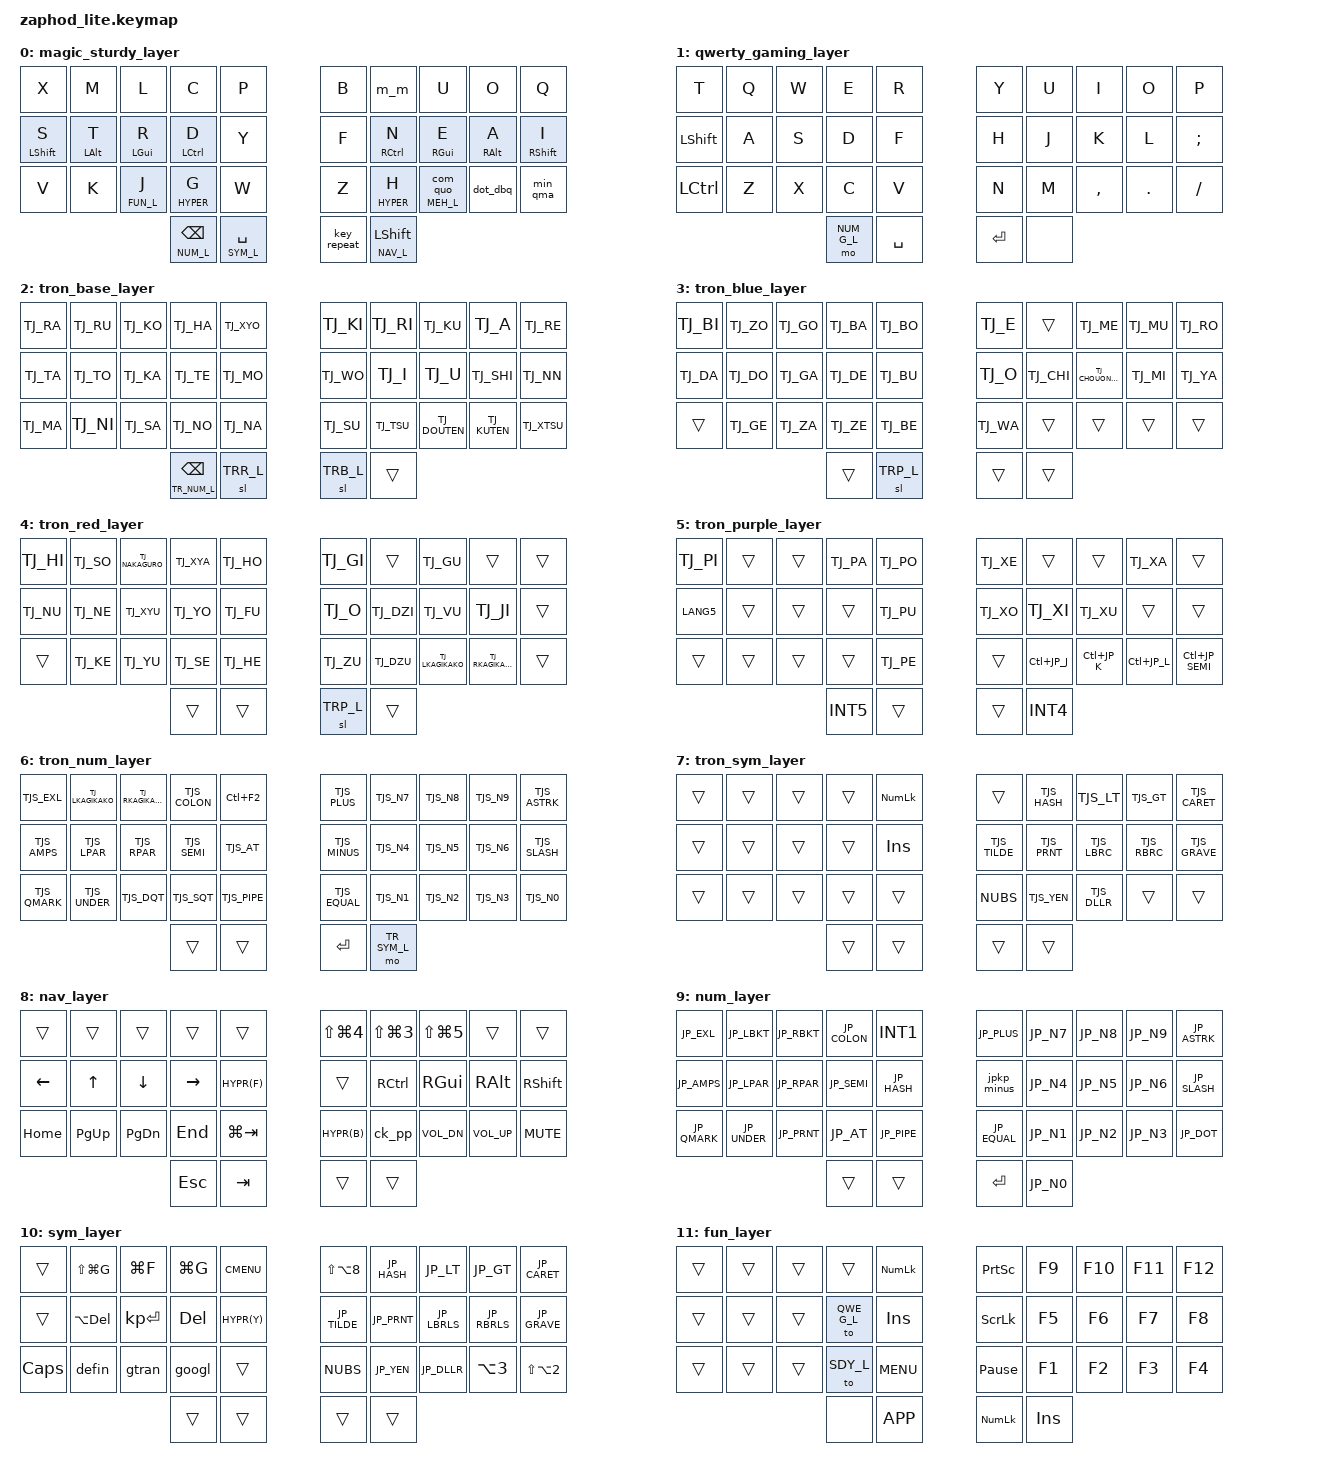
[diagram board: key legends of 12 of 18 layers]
// -*- mode: c++ -*-


/*
 * Copyright (c) 2021 Pete Johanson
 *
 * SPDX-License-Identifier: MIT
 */

#include <behaviors.dtsi>
#include <dt-bindings/zmk/keys.h>
#include <dt-bindings/zmk/bt.h>
#include <dt-bindings/zmk/outputs.h>

#define SDY_L 0
#define QWE_G_L 1

#define TRN_L 2
#define TRB_L 3
#define TRR_L 4
#define TRP_L 5

#define TR_NUM_L 6
#define TR_SYM_L 7

#define NAV_L 8
#define NUM_L 9
#define SYM_L 10
#define FUN_L 11

#define NUM_G_L 12

#define NUM_W_L 13
#define BLE_L 14
#define MEH_L 15
#define SRT_EXW_MAC_L 16
#define SRT_EXL_L 17

#define HYPER LS(LA(LG(LCTL)))
#define MEH(key) LS(LA(LC(key)))
#define HYPR(key) LS(LA(LG(LC(key))))


// JIS

#include "jis.h"
#include "tron.h"

// Using layer taps on thumbs, having quick tap as well helps w/ repeating space/backspace
&lt { quick_tap_ms = <150>; };

&sk {  // sticky-key config
  release-after-ms = <1000>;  // release after 0.6s
  quick-release;             // no double capitalization when rolling keys
};

&sl {  // sticky-layer config
  release-after-ms = <5000>;  
  quick-release;             // no double capitalization when rolling keys
};

&caps_word {
  continue-list = <UNDERSCORE INT1 MINUS AMPS BACKSPACE>;
};

/ {
  combos {
    compatible = "zmk,combos";
    // system
    ble_mo {
      timeout-ms = <50>;
      key-positions = <9 19 29>;
      bindings = <&mo BLE_L>;
      require-prior-idle-ms = <180>;
    };
    // layers
    num_sticky_combo {
      timeout-ms = <50>;
      key-positions = <12 30>;
      bindings = <&sl NUM_L>;
      require-prior-idle-ms = <180>;
    };
    nav_sticky_combo {
      timeout-ms = <50>;
      key-positions = <11 30>;
      bindings = <&sl NAV_L>;
      require-prior-idle-ms = <180>;
    };
    sym_sticky_combo {
      timeout-ms = <50>;
      key-positions = <10 30>;
      bindings = <&sl SYM_L>;
      require-prior-idle-ms = <180>;
    };
    num_word_combo {
      timeout-ms = <50>;
      key-positions = <30 33>;
      bindings = <&tog NUM_W_L>;
      require-prior-idle-ms = <180>;
    };
    fun_alt_combo {
      timeout-ms = <50>;
      key-positions = <8 18 28>;
      bindings = <&mo FUN_L>;
      require-prior-idle-ms = <180>;
    };
    // English
    caps_word_combo {
      timeout-ms = <50>;
      key-positions = <31 32>;
      bindings = <&caps_word>;
      require-prior-idle-ms = <180>;
    };
    sorcery_magic2 {
      timeout-ms = <50>;
      key-positions = <3 6>;
      layers = <0 2>;
      bindings = <&kp LS(NUBS)>;
      require-prior-idle-ms = <180>;
    };
    // Numword
    panic {
      timeout-ms = <50>;
      key-positions = <0 10>;
      layers = <13>;
      bindings = <&to SDY_L>;
      require-prior-idle-ms = <180>;
    };
    numword_ret {
      timeout-ms = <50>;
      key-positions = <18 8>;
      layers = <13>;
      require-prior-idle-ms = <180>;
      bindings = <&nw_ret>;
    }; 
    // movement
    backward_char {
      timeout-ms = <50>;
      key-positions = <12 22>;
      bindings = <&kp LEFT>;
      require-prior-idle-ms = <180>;
    };
    forward_char {
      timeout-ms = <50>;
      key-positions = <17 27>;
      bindings = <&kp RIGHT>;
      require-prior-idle-ms = <180>;
    };
    backward_sentence {
      timeout-ms = <50>;
      key-positions = <14 24>;
      bindings = <&kp HOME>;
      require-prior-idle-ms = <180>;
    };      
    forward_sentence {
      timeout-ms = <50>;
      key-positions = <15 25>;
      bindings = <&kp END>;
      require-prior-idle-ms = <180>;
    };
    previous_line {
      timeout-ms = <50>;
      key-positions = <13 22>;
      bindings = <&kp UP>;
      require-prior-idle-ms = <180>;
    };
    next_line {
      timeout-ms = <50>;
      key-positions = <16 27>;
      bindings = <&kp DOWN>;
      require-prior-idle-ms = <180>;
    };
    up {
      timeout-ms = <50>;
      key-positions = <13 23>;
      bindings = <&kp UP>;
      require-prior-idle-ms = <180>;
    };
    down {
      timeout-ms = <50>;
      key-positions = <16 26>;
      bindings = <&kp DOWN>;
      require-prior-idle-ms = <180>;
    };
    page_up_combo {
      timeout-ms = <50>;
      key-positions = <11 22>;
      bindings = <&kp PG_UP>;
      require-prior-idle-ms = <180>;
    };
    page_down_combo {
      timeout-ms = <50>;
      key-positions = <18 27>;
      bindings = <&kp PG_DN>;
      require-prior-idle-ms = <180>;
    };  
    // controls    
    tab_combo {
      timeout-ms = <50>;
      key-positions = <10 20>;
      bindings = <&kp TAB>;
      require-prior-idle-ms = <180>;
    };
    esc_combo {
      timeout-ms = <50>;
      key-positions = <0 10>;
      bindings = <&kp ESC>;
      require-prior-idle-ms = <180>;
    };
    bksp_word_combo_mac {
      timeout-ms = <50>;
      key-positions = <15 16>;
      layers = <0 2>;
      bindings = <&kp LA(BSPC)>;
      require-prior-idle-ms = <180>;
    };
    del_word_mac {
      timeout-ms = <50>;
      key-positions = <13 14>;
      layers = <0 2>;
      bindings = <&kp LA(DEL)>;
      require-prior-idle-ms = <180>;
    };
    spc_combo {
      layers = <2 3 4 5 6 7>;
      timeout-ms = <30>;
      key-positions = <11 21>;
      bindings = <&kp SPACE>;
      require-prior-idle-ms = <180>;
    };
    ret_combo {
      timeout-ms = <50>;
      key-positions = <18 8>;
      bindings = <&kp RET>;
      require-prior-idle-ms = <180>;
    };
    // shortcuts
    undo_mac {
      timeout-ms = <50>;
      key-positions = <3 4>;
      bindings = <&undo_mac_b>;
      require-prior-idle-ms = <180>;
    };
    save_mac {
      timeout-ms = <50>;
      key-positions = <28 18>;
      layers = <0 2>;
      bindings = <&kp LG(S)>;
      require-prior-idle-ms = <180>;
    };
    copy_mac {
      timeout-ms = <50>;
      key-positions = <1 11>;
      layers = <0 2>;
      bindings = <&copy_mac_b>;
      require-prior-idle-ms = <180>;
    };
    paste_mac {
      timeout-ms = <50>;
      key-positions = <2 12>;
      layers = <0 2>;
      bindings = <&paste_mac_b>;
      require-prior-idle-ms = <180>;
    };
    // Japanese language
    eisu_combo {
      timeout-ms = <50>;
      key-positions = <3 13>;
      layers = <0 2>;
      bindings = <&_EISU>;
      require-prior-idle-ms = <180>;
    };
    kana_combo {
      timeout-ms = <50>;
      key-positions = <6 16>;
      layers = <0 2>;
      bindings = <&_KANA>;
      require-prior-idle-ms = <180>;
    };
    hiragana_mac {
      layers = <1 2 3 4 5 6>;
      timeout-ms = <50>;
      key-positions = <4 14>;
      bindings = <&kp LC(J)>;
      require-prior-idle-ms = <180>;
    };
    katakana_mac {
      layers = <1 2 3 4 5 6>;
      timeout-ms = <50>;
      key-positions = <5 15>;
      bindings = <&kp LC(K)>;
      require-prior-idle-ms = <180>;
    };
    // select word-line
    selword_mac {
      timeout-ms = <50>;
      key-positions = <13 16>;
      layers = <0 2>;
      bindings = <&selw_sell_mac>;
      require-prior-idle-ms = <180>;
    };
    selword_rep_mac {
      layers = <14>;
      timeout-ms = <50>;
      key-positions = <13 16>;
      bindings = <&selword_f_mac_rep>;
      require-prior-idle-ms = <180>;
    };
    selline_rep {
      layers = <15>;
      timeout-ms = <50>;
      key-positions = <13 16>;
      bindings = <&selline_f_rep>;
      require-prior-idle-ms = <180>;
    };
    squot {
      timeout-ms = <50>;
      key-positions = <7 17>;
      bindings = <&kp LS(N7)>;
      require-prior-idle-ms = <180>;
    };
    dquot {
      timeout-ms = <50>;
      key-positions = <9 19>;
      bindings = <&kp LS(N2)>;
      require-prior-idle-ms = <180>;
    };
  };
};

/ {
  macros {
  TJ_GI: tron_gi {
      compatible = "zmk,behavior-macro";
      #binding-cells = <0>;
      bindings
        = <&macro_tap &kp TJ_KI>
        , <&macro_tap &kp TJ_DAKUTEN>
        ;
    };
  TJ_GE: tron_ge {
      compatible = "zmk,behavior-macro";
      #binding-cells = <0>;
      bindings
        = <&macro_tap &kp TJ_KE>
        , <&macro_tap &kp TJ_DAKUTEN>
        ;
    };
  TJ_GU: tron_gu {
      compatible = "zmk,behavior-macro";
      #binding-cells = <0>;
      bindings
        = <&macro_tap &kp TJ_KU>
        , <&macro_tap &kp TJ_DAKUTEN>
        ;
    };
  TJ_DZI: tron_dzi {
      compatible = "zmk,behavior-macro";
      #binding-cells = <0>;
      bindings
        = <&macro_tap &kp TJ_CHI>
        , <&macro_tap &kp TJ_DAKUTEN>
        ;
    };
  TJ_VU: tron_vu {
      compatible = "zmk,behavior-macro";
      #binding-cells = <0>;
      bindings
        = <&macro_tap &kp TJ_U>
        , <&macro_tap &kp TJ_DAKUTEN>
        ;
    };
  TJ_JI: tron_ji {
      compatible = "zmk,behavior-macro";
      #binding-cells = <0>;
      bindings
        = <&macro_tap &kp TJ_SHI>
        , <&macro_tap &kp TJ_DAKUTEN>
        ;
    };
  TJ_ZU: tron_zu {
      compatible = "zmk,behavior-macro";
      #binding-cells = <0>;
      bindings
        = <&macro_tap &kp TJ_SU>
        , <&macro_tap &kp TJ_DAKUTEN>
        ;
    };
  TJ_DZU: tron_dzu {
      compatible = "zmk,behavior-macro";
      #binding-cells = <0>;
      bindings
        = <&macro_tap &kp TJ_TSU>
        , <&macro_tap &kp TJ_DAKUTEN>
        ;
    };
  TJ_BI: tron_bi {
      compatible = "zmk,behavior-macro";
      #binding-cells = <0>;
      bindings
        = <&macro_tap &kp TJ_HI>
        , <&macro_tap &kp TJ_DAKUTEN>
        ;
    };
  TJ_ZO: tron_zo {
      compatible = "zmk,behavior-macro";
      #binding-cells = <0>;
      bindings
        = <&macro_tap &kp TJ_SO>
        , <&macro_tap &kp TJ_DAKUTEN>
        ;
    };
  TJ_GO: tron_go {
      compatible = "zmk,behavior-macro";
      #binding-cells = <0>;
      bindings
        = <&macro_tap &kp TJ_KO>
        , <&macro_tap &kp TJ_DAKUTEN>
        ;
    };
  TJ_BA: tron_ba {
      compatible = "zmk,behavior-macro";
      #binding-cells = <0>;
      bindings
        = <&macro_tap &kp TJ_HA>
        , <&macro_tap &kp TJ_DAKUTEN>
        ;
    };
  TJ_BO: tron_bo {
      compatible = "zmk,behavior-macro";
      #binding-cells = <0>;
      bindings
        = <&macro_tap &kp TJ_HO>
        , <&macro_tap &kp TJ_DAKUTEN>
        ;
    };
  TJ_DA: tron_da {
      compatible = "zmk,behavior-macro";
      #binding-cells = <0>;
      bindings
        = <&macro_tap &kp TJ_TA>
        , <&macro_tap &kp TJ_DAKUTEN>
        ;
    };
  TJ_DO: tron_do {
      compatible = "zmk,behavior-macro";
      #binding-cells = <0>;
      bindings
        = <&macro_tap &kp TJ_TO>
        , <&macro_tap &kp TJ_DAKUTEN>
        ;
    };
  TJ_GA: tron_ga {
      compatible = "zmk,behavior-macro";
      #binding-cells = <0>;
      bindings
        = <&macro_tap &kp TJ_KA>
        , <&macro_tap &kp TJ_DAKUTEN>
        ;
    };
  TJ_DE: tron_de {
      compatible = "zmk,behavior-macro";
      #binding-cells = <0>;
      bindings
        = <&macro_tap &kp TJ_TE>
        , <&macro_tap &kp TJ_DAKUTEN>
        ;
    };
  TJ_BU: tron_bu {
      compatible = "zmk,behavior-macro";
      #binding-cells = <0>;
      bindings
        = <&macro_tap &kp TJ_FU>
        , <&macro_tap &kp TJ_DAKUTEN>
        ;
    };
  TJ_ZE: tron_ze {
      compatible = "zmk,behavior-macro";
      #binding-cells = <0>;
      bindings
        = <&macro_tap &kp TJ_SE>
        , <&macro_tap &kp TJ_DAKUTEN>
        ;
    };
  TJ_ZA: tron_za {
      compatible = "zmk,behavior-macro";
      #binding-cells = <0>;
      bindings
        = <&macro_tap &kp TJ_SA>
        , <&macro_tap &kp TJ_DAKUTEN>
        ;
    };
  TJ_BE: tron_be {
      compatible = "zmk,behavior-macro";
      #binding-cells = <0>;
      bindings
        = <&macro_tap &kp TJ_HE>
        , <&macro_tap &kp TJ_DAKUTEN>
        ;
    };
  TJ_PA: tron_pa {
      compatible = "zmk,behavior-macro";
      #binding-cells = <0>;
      bindings
        = <&macro_tap &kp TJ_HA>
        , <&macro_tap &kp TJ_HANDAKUTEN>
        ;
    };
  TJ_PI: tron_pi {
      compatible = "zmk,behavior-macro";
      #binding-cells = <0>;
      bindings
        = <&macro_tap &kp TJ_HI>
        , <&macro_tap &kp TJ_HANDAKUTEN>
        ;
    };
  TJ_PU: tron_pu {
      compatible = "zmk,behavior-macro";
      #binding-cells = <0>;
      bindings
        = <&macro_tap &kp TJ_FU>
        , <&macro_tap &kp TJ_HANDAKUTEN>
        ;
    };
  TJ_PE: tron_pe {
      compatible = "zmk,behavior-macro";
      #binding-cells = <0>;
      bindings
        = <&macro_tap &kp TJ_HE>
        , <&macro_tap &kp TJ_HANDAKUTEN>
        ;
    };
  TJ_PO: tron_po {
      compatible = "zmk,behavior-macro";
      #binding-cells = <0>;
      bindings
        = <&macro_tap &kp TJ_HO>
        , <&macro_tap &kp TJ_HANDAKUTEN>
        ;
    };
  TJ_LKAGIKAKO: tron_lkagikako {
      compatible = "zmk,behavior-macro";
      #binding-cells = <0>;
      bindings
        = <&macro_press &kp LSHFT>
        , <&macro_tap &kp TJ_HANDAKUTEN>
        , <&macro_release &kp LSHFT>
        ;
    };
  TJ_RKAGIKAKO: tron_rkagikako {
      compatible = "zmk,behavior-macro";
      #binding-cells = <0>;
      bindings
        = <&macro_press &kp LSHFT>
        , <&macro_tap &kp TJ_MU>
        , <&macro_release &kp LSHFT>
        ;
    };
  TJS_QMARK: tron_question_mark {
      compatible = "zmk,behavior-macro";
      #binding-cells = <0>;
      bindings
        = <&macro_tap &kp TJ_NAKAGURO>
        , <&macro_tap &kp LC(L)>
        ;      
    };
  TJS_SLASH: tron_slash {
      compatible = "zmk,behavior-macro";
      #binding-cells = <0>;
      bindings
        = <&macro_tap &kp TJ_ME>
        , <&macro_tap &kp LC(L)>
        ;      
    };
  TJS_SEMI: tron_semi_colon {
      compatible = "zmk,behavior-macro";
      #binding-cells = <0>;
      bindings
        = <&macro_tap &kp TJ_RE>
        , <&macro_tap &kp LC(L)>
        ;      
    };
  TJS_COLON: tron_colon {
      compatible = "zmk,behavior-macro";
      #binding-cells = <0>;
      bindings
        = <&macro_tap &kp TJ_KE>
        , <&macro_tap &kp LC(L)>
        ;      
    };
  TJS_N1: tron_1 {
      compatible = "zmk,behavior-macro";
      #binding-cells = <0>;
      bindings
        = <&macro_tap &kp TJ_NU>
        , <&macro_tap &kp LC(L)>
        ;      
    };
  TJS_N2: tron_2 {
      compatible = "zmk,behavior-macro";
      #binding-cells = <0>;
      bindings
        = <&macro_tap &kp TJ_FU>
        , <&macro_tap &kp LC(L)>
        ;      
    };
  TJS_N3: tron_3 {
      compatible = "zmk,behavior-macro";
      #binding-cells = <0>;
      bindings
        = <&macro_tap &kp TJ_A>
        , <&macro_tap &kp LC(L)>
        ;      
    };
  TJS_N4: tron_4 {
      compatible = "zmk,behavior-macro";
      #binding-cells = <0>;
      bindings
        = <&macro_tap &kp TJ_U>
        , <&macro_tap &kp LC(L)>
        ;      
    };
  TJS_N5: tron_5 {
      compatible = "zmk,behavior-macro";
      #binding-cells = <0>;
      bindings
        = <&macro_tap &kp TJ_E>
        , <&macro_tap &kp LC(L)>
        ;      
    };
  TJS_N6: tron_6 {
      compatible = "zmk,behavior-macro";
      #binding-cells = <0>;
      bindings
        = <&macro_tap &kp TJ_O>
        , <&macro_tap &kp LC(L)>
        ;      
    };
  TJS_N7: tron_7 {
      compatible = "zmk,behavior-macro";
      #binding-cells = <0>;
      bindings
        = <&macro_tap &kp TJ_YA>
        , <&macro_tap &kp LC(L)>
        ;      
    };
  TJS_N8: tron_8 {
      compatible = "zmk,behavior-macro";
      #binding-cells = <0>;
      bindings
        = <&macro_tap &kp TJ_YU>
        , <&macro_tap &kp LC(L)>
        ;      
    };
  TJS_N9: tron_9 {
      compatible = "zmk,behavior-macro";
      #binding-cells = <0>;
      bindings
        = <&macro_tap &kp TJ_YO>
        , <&macro_tap &kp LC(L)>
        ;      
    };
  TJS_N0: tron_0 {
      compatible = "zmk,behavior-macro";
      #binding-cells = <0>;
      bindings
        = <&macro_tap &kp TJ_WA>
        , <&macro_tap &kp LC(L)>
        ;      
    };
  TJS_AT: tron_at {
      compatible = "zmk,behavior-macro";
      #binding-cells = <0>;
      bindings
        = <&macro_tap &kp TJ_DAKUTEN>
        , <&macro_tap &kp LC(L)>
        ;      
    };
  TJS_MINUS: tron_minus {
      compatible = "zmk,behavior-macro";
      #binding-cells = <0>;
      bindings
        = <&macro_tap &kp TJ_HO>
        , <&macro_tap &kp LC(L)>
        ;      
    };
  TJS_CARET: tron_circumflex {
      compatible = "zmk,behavior-macro";
      #binding-cells = <0>;
      bindings
        = <&macro_tap &kp TJ_HE>
        , <&macro_tap &kp LC(L)>
        ;      
    };
  TJS_UNDER: tron_underscore {
      compatible = "zmk,behavior-macro";
      #binding-cells = <0>;
      bindings
        = <&macro_tap &kp TJ_RO>
        , <&macro_tap &kp LC(L)>
        ;      
    };
  TJS_YEN: tron_yen {
      compatible = "zmk,behavior-macro";
      #binding-cells = <0>;
      bindings
        = <&macro_tap &kp TJ_CHOUONNPU>
        , <&macro_tap &kp LC(L)>
        ;      
    };
  TJS_EXL: tron_exclamation_mark {
      compatible = "zmk,behavior-macro";
      #binding-cells = <0>;
      bindings
        = <&macro_press &kp LSHFT>
        , <&macro_tap &kp TJ_NU>
        , <&macro_release &kp LSHFT>
        , <&macro_tap &kp LC(L)>
        ;      
    };
  TJS_DQT: tron_double_quote {
      compatible = "zmk,behavior-macro";
      #binding-cells = <0>;
      bindings
        = <&macro_press &kp LSHFT>
        , <&macro_tap &kp TJ_FU>
        , <&macro_release &kp LSHFT>
        , <&macro_tap &kp LC(L)>
        ;      
    };
  TJS_HASH: tron_hash {
      compatible = "zmk,behavior-macro";
      #binding-cells = <0>;
      bindings
        = <&macro_press &kp LSHFT>
        , <&macro_tap &kp TJ_A>
        , <&macro_release &kp LSHFT>
        , <&macro_tap &kp LC(L)>
        ;      
    };
  TJS_DLLR: tron_dollar {
      compatible = "zmk,behavior-macro";
      #binding-cells = <0>;
      bindings
        = <&macro_press &kp LSHFT>
        , <&macro_tap &kp TJ_U>
        , <&macro_release &kp LSHFT>
        , <&macro_tap &kp LC(L)>
        ;      
    };
  TJS_PRNT: tron_percent {
      compatible = "zmk,behavior-macro";
      #binding-cells = <0>;
      bindings
        = <&macro_press &kp LSHFT>
        , <&macro_tap &kp TJ_E>
        , <&macro_release &kp LSHFT>
        , <&macro_tap &kp LC(L)>
        ;      
    };
  TJS_AMPS: tron_ampersand {
      compatible = "zmk,behavior-macro";
      #binding-cells = <0>;
      bindings
        = <&macro_press &kp LSHFT>
        , <&macro_tap &kp TJ_O>
        , <&macro_release &kp LSHFT>
        , <&macro_tap &kp LC(L)>
        ;      
    };
  TJS_SQT: tron_single_quote {
      compatible = "zmk,behavior-macro";
      #binding-cells = <0>;
      bindings
        = <&macro_press &kp LSHFT>
        , <&macro_tap &kp TJ_YA>
        , <&macro_release &kp LSHFT>
        , <&macro_tap &kp LC(L)>
        ;      
    };
  TJS_LPAR: tron_left_parenthesis {
      compatible = "zmk,behavior-macro";
      #binding-cells = <0>;
      bindings
        = <&macro_press &kp LSHFT>
        , <&macro_tap &kp TJ_YU>
        , <&macro_release &kp LSHFT>
        , <&macro_tap &kp LC(L)>
        ;      
    };
  TJS_RPAR: tron_right_parenthesis {
      compatible = "zmk,behavior-macro";
      #binding-cells = <0>;
      bindings
        = <&macro_press &kp LSHFT>
        , <&macro_tap &kp TJ_YO>
        , <&macro_release &kp LSHFT>
        , <&macro_tap &kp LC(L)>
        ;      
    };
  TJS_EQUAL: tron_equal {
      compatible = "zmk,behavior-macro";
      #binding-cells = <0>;
      bindings
        = <&macro_press &kp LSHFT>
        , <&macro_tap &kp TJ_HO>
        , <&macro_release &kp LSHFT>
        , <&macro_tap &kp LC(L)>
        ;      
    };
  TJS_TILDE: tron_tilde {
      compatible = "zmk,behavior-macro";
      #binding-cells = <0>;
      bindings
        = <&macro_press &kp LSHFT>
        , <&macro_tap &kp TJ_HE>
        , <&macro_release &kp LSHFT>
        , <&macro_tap &kp LC(L)>
        ;      
    };
  TJS_PIPE: tron_pipe {
      compatible = "zmk,behavior-macro";
      #binding-cells = <0>;
      bindings
        = <&macro_press &kp LSHFT>
        , <&macro_tap &kp TJ_CHOUONNPU>
        , <&macro_release &kp LSHFT>
        , <&macro_tap &kp LC(L)>
        ;      
    };
  TJS_GRAVE: tron_grave {
      compatible = "zmk,behavior-macro";
      #binding-cells = <0>;
      bindings
        = <&macro_press &kp LSHFT>
        , <&macro_tap &kp TJ_DAKUTEN>
        , <&macro_release &kp LSHFT>
        , <&macro_tap &kp LC(L)>
        ;      
    };
  TJS_LBRC: tron_left_brace {
      compatible = "zmk,behavior-macro";
      #binding-cells = <0>;
      bindings
        = <&macro_press &kp LSHFT>
        , <&macro_tap &kp TJ_HANDAKUTEN>
        , <&macro_release &kp LSHFT>
        , <&macro_tap &kp LC(L)>
        ;      
    };
  TJS_RBRC: tron_right_brace {
      compatible = "zmk,behavior-macro";
      #binding-cells = <0>;
      bindings
        = <&macro_press &kp LSHFT>
        , <&macro_tap &kp TJ_MU>
        , <&macro_release &kp LSHFT>
        , <&macro_tap &kp LC(L)>
        ;      
    };
  TJS_PLUS: tron_plus {
      compatible = "zmk,behavior-macro";
      #binding-cells = <0>;
      bindings
        = <&macro_press &kp LSHFT>
        , <&macro_tap &kp TJ_RE>
        , <&macro_release &kp LSHFT>
        , <&macro_tap &kp LC(L)>
        ;      
    };
  TJS_ASTRK: tron_asterisk {
      compatible = "zmk,behavior-macro";
      #binding-cells = <0>;
      bindings
        = <&macro_press &kp LSHFT>
        , <&macro_tap &kp TJ_KE>
        , <&macro_release &kp LSHFT>
        , <&macro_tap &kp LC(L)>
        ;      
    };
  TJS_LT: tron_less_than {
      compatible = "zmk,behavior-macro";
      #binding-cells = <0>;
      bindings
        = <&macro_press &kp LSHFT>
        , <&macro_tap &kp TJ_DOUTEN>
        , <&macro_release &kp LSHFT>
        , <&macro_tap &kp LC(L)>
        ;      
    };
  TJS_GT: tron_greater_than {
      compatible = "zmk,behavior-macro";
      #binding-cells = <0>;
      bindings
        = <&macro_press &kp LSHFT>
        , <&macro_tap &kp TJ_KUTEN>
        , <&macro_release &kp LSHFT>
        , <&macro_tap &kp LC(L)>
        ;      
    };
  _EISU: _eisu {
      compatible = "zmk,behavior-macro";
      #binding-cells = <0>;
      bindings
        = <&macro_tap &kp LANG2>
        , <&macro_tap &to SDY_L>
        ;
    };
  _KANA: _kana {
      compatible = "zmk,behavior-macro";
      #binding-cells = <0>;
      bindings
        = <&macro_tap &kp LANG1>
        , <&macro_tap &to TRN_L>
        ;
    };
  googl: googl {
      compatible = "zmk,behavior-macro";
      #binding-cells = <0>;
      bindings
        = <&macro_tap &kp LG(C)>
        , <&macro_tap &kp LG(SPACE)>
        , <&macro_tap &kp G &kp SPACE>
        , <&macro_tap &kp LG(V) &kp RET>
        ;
    };
  gtran: gtran {
      compatible = "zmk,behavior-macro";
      #binding-cells = <0>;
      bindings
        = <&macro_tap &kp LG(C)>
        , <&macro_tap &kp LG(SPACE)>
        , <&macro_tap &kp T &kp SPACE>
        , <&macro_tap &kp LG(V) &kp RET>
        ;
    };
  defin: defin {
      compatible = "zmk,behavior-macro";
      #binding-cells = <0>;
      bindings
        = <&macro_tap &kp LG(C)>
        , <&macro_tap &kp LG(SPACE)>
        , <&macro_tap &kp D &kp SPACE>
        , <&macro_tap &kp LG(V)>
        , <&macro_wait_time 50>
        , <&kp RET>
        ;
    };

  nw_spc: nw_spc {
      compatible = "zmk,behavior-macro";
      #binding-cells = <0>;
      bindings
        = <&macro_press &kp SPACE>
        , <&macro_tap &tog NUM_W_L>
        , <&macro_pause_for_release>
        , <&macro_release &kp SPACE>
        ;
    };
  nw_ret: nw_ret {
      compatible = "zmk,behavior-macro";
      #binding-cells = <0>;
      bindings
        = <&macro_press &kp RET>
        , <&macro_tap &tog NUM_W_L>
        , <&macro_pause_for_release>
        , <&macro_release &kp RET>
        ;
    };
  selword_f_mac: select_word_mac_forwards {
      compatible = "zmk,behavior-macro";
      #binding-cells = <0>;
      bindings
        = <&macro_tap &kp LA(RIGHT)>
        , <&macro_tap &kp LA(LEFT)>
        , <&macro_tap &kp LA(LS(RIGHT))>
        , <&macro_tap &sl SRT_EXW_MAC_L>
        ;
    };
  selword_f_mac_rep: select_word_mac_forwards_repeat {
      compatible = "zmk,behavior-macro";
      #binding-cells = <0>;
      bindings
        = <&macro_tap &kp LA(LS(RIGHT))>
        , <&macro_tap &sl SRT_EXW_MAC_L>
        ;
    };
  selline_f: select_line_forwards {
      compatible = "zmk,behavior-macro";
      #binding-cells = <0>;
      bindings
        = <&macro_tap &kp HOME &kp LS(END)>
        , <&macro_tap &sl SRT_EXL_L>
        ;
    };
  selline_f_rep: select_line_forwards_repeat {
      compatible = "zmk,behavior-macro";
      #binding-cells = <0>;
      bindings    
        = <&macro_tap &kp LS(DOWN)>
        , <&macro_tap &kp LS(END)>
        , <&macro_tap &sl SRT_EXL_L>
        ;
    };
  undo_mac_b: undo_mac_b {
      compatible = "zmk,behavior-macro";
      #binding-cells = <0>;
      bindings =  <&kp (LG(Z))>;
    };
  copy_mac_b: copy_mac_b {
      compatible = "zmk,behavior-macro";
      #binding-cells = <0>;
      bindings =  <&kp (LG(C))>;
    };
  paste_mac_b: paste_mac_b {
      compatible = "zmk,behavior-macro";
      #binding-cells = <0>;
      bindings =  <&kp (LG(V))>;
    };
  };
  
  };
/ {
  behaviors {
  hm: homerow_mods {
      compatible = "zmk,behavior-hold-tap";
      #binding-cells = <2>;
      tapping_term_ms = <300>;
      require-prior-idle-ms = <180>;
      flavor = "tap-preferred";
      bindings = <&kp>, <&kp>;
    };
  hmr: homerow_mods_right {
      compatible = "zmk,behavior-hold-tap";
      #binding-cells = <2>;
      tapping_term_ms = <300>;
      require-prior-idle-ms = <180>;
      flavor = "tap-preferred";
      bindings = <&kp>, <&kp>;
      hold-trigger-key-positions = <0 1 2 3 4 10 11 12 13 14 20 21 22 23 24 30 31 32 33>; 
    };
  hml: homerow_mods_left {
      compatible = "zmk,behavior-hold-tap";
      #binding-cells = <2>;
      tapping_term_ms = <300>;
      require-prior-idle-ms = <180>;
      flavor = "tap-preferred";
      bindings = <&kp>, <&kp>;
      hold-trigger-key-positions = <5 6 7 8 9 15 16 17 18 19 25 26 27 28 29 30 31 32 33>; 
    };
    
  com_quo: comma_quot {
      compatible = "zmk,behavior-mod-morph";
      #binding-cells = <0>;
      bindings = <&kp JP_COMMA>, <&kp JP_SQT>;
      mods = <(MOD_LSFT)>;
    };

  hmr_com_quo: homerow_mods_right_comma_quote {
      compatible = "zmk,behavior-hold-tap";
      #binding-cells = <2>;
      tapping_term_ms = <300>;
      require-prior-idle-ms = <180>;
      flavor = "tap-preferred";
      bindings = <&mo>, <&com_quo>;
      hold-trigger-key-positions = <0 1 2 3 4 10 11 12 13 14 20 21 22 23 24 30 31 32 33>; 
    };
    
  dot_dbq: dot_doublequote {
      compatible = "zmk,behavior-mod-morph";
      #binding-cells = <0>;
      bindings = <&kp JP_DOT>, <&kp JP_DQT>;
      mods = <(MOD_LSFT)>;
    };
  min_qma: min_qma {
      compatible = "zmk,behavior-mod-morph";
      #binding-cells = <0>;
      bindings = <&kp JP_MINUS>, <&kp JP_QMARK>;
      mods = <(MOD_LSFT)>;
    };
  ck_pp: ck_pp {
      compatible = "zmk,behavior-mod-morph";
      #binding-cells = <0>;
      bindings = <&kp C_PP>, <&kp K_PP>;
      mods = <(MOD_LSFT)>;
    };
  jpkp_minus: jpkp_minus {
      compatible = "zmk,behavior-mod-morph";
      #binding-cells = <0>;
      bindings = <&kp JP_MINUS>, <&kp KP_MINUS>;
      mods = <(MOD_LSFT)>;
    };
  ss_mo: ss_mo {
      compatible = "zmk,behavior-hold-tap";
      #binding-cells = <2>;
      flavor = "tap-preferred";
      tapping-term-ms = <300>;
      bindings = <&mo>, <&sk>;
    };
  selw_sell_mac: selword_selline_mac {
      compatible = "zmk,behavior-mod-morph";
      #binding-cells = <0>;
      bindings = <&selword_f_mac>, <&selline_f>;
      mods = <(MOD_LSFT|MOD_RSFT)>;
    };
  selw_sela_mac: selword_selall_mac {
      compatible = "zmk,behavior-mod-morph";
      #binding-cells = <0>;
      bindings = <&selword_f_mac>, <&kp LG(A)>;
      mods = <(MOD_LALT|MOD_RALT)>;
    };
  undo_redo_mac: undo_redo {
      compatible = "zmk,behavior-mod-morph";
      #binding-cells = <0>;
      bindings = <&undo_mac_b>, <&kp LS(LG(Z))>;
      mods = <(MOD_LSFT|MOD_RSFT)>;
    };
  paste_without_mac: paste_without {
      compatible = "zmk,behavior-mod-morph";
      #binding-cells = <0>;
      bindings = <&paste_mac_b>, <&kp LS(LA(LG(V)))>;
      mods = <(MOD_LSFT|MOD_RSFT)>;
    };
  copy_cut_mac: copy_cut {
      compatible = "zmk,behavior-mod-morph";
      #binding-cells = <0>;
      bindings = <&copy_mac_b>, <&kp LG(X)>;
      mods = <(MOD_LSFT|MOD_RSFT)>;
    };
   m_m: magic_magic {
      compatible = "zmk,behavior-adaptive-key";
      #binding-cells = <0>;
      bindings = <&kp M>;
      mt_m { trigger-keys = <M>; max-prior-idle-ms = <300>; bindings = <&kp T>; };
      mt_l { trigger-keys = <L>; max-prior-idle-ms = <300>; bindings = <&kp R>; };
      mt_x { trigger-keys = <T>; max-prior-idle-ms = <300>; bindings = <&kp T>; };
      mt_u { trigger-keys = <U>; max-prior-idle-ms = <300>; bindings = <&kp E>; };
      mt_o { trigger-keys = <O>; max-prior-idle-ms = <300>; bindings = <&kp A>; };
      mt_t { trigger-keys = <T>; max-prior-idle-ms = <300>; bindings = <&kp M>; };
      mt_r { trigger-keys = <R>; max-prior-idle-ms = <300>; bindings = <&kp L>; };
      mt_d { trigger-keys = <D>; max-prior-idle-ms = <300>; bindings = <&kp Y>; };
      mt_e { trigger-keys = <E>; max-prior-idle-ms = <300>; bindings = <&kp U>; };
      mt_a { trigger-keys = <A>; max-prior-idle-ms = <300>; bindings = <&kp O>; };
      mt_c { trigger-keys = <C>; max-prior-idle-ms = <300>; bindings = <&kp Y>; };
      mt_g { trigger-keys = <G>; max-prior-idle-ms = <300>; bindings = <&kp Y>; };
      mt_p { trigger-keys = <P>; max-prior-idle-ms = <300>; bindings = <&kp Y>; };
      mt_y { trigger-keys = <Y>; max-prior-idle-ms = <300>; bindings = <&kp P>; };
      mt_v { trigger-keys = <V>; max-prior-idle-ms = <300>; bindings = <&kp S>; };      
      };
      
    }; 


  };
  

/ {
  keymap {
    compatible = "zmk,keymap";

    magic_sturdy_layer {
      bindings = <
        &kp X        &kp M       &kp L        &kp C          &kp P    &kp B  &m_m          &kp U                 &kp O        &kp Q
        &hml LSHFT S &hml LALT T &hml LGUI R  &hml LCTRL D   &kp Y    &kp F  &hmr RCTRL N  &hmr RGUI E           &hmr RALT A  &hmr RSHFT I
        &kp V        &kp K       &lt FUN_L J  &hml HYPER G   &kp W    &kp Z  &hmr HYPER H  &hmr_com_quo MEH_L 0  &dot_dbq     &min_qma
        &lt NUM_L BKSP   &lt SYM_L SPACE    &key_repeat &ss_mo NAV_L LSHIFT
        >;
    };

        qwerty_gaming_layer {
      bindings = <
        &kp T      &kp Q     &kp W    &kp E    &kp R         &kp Y    &kp U    &kp I     &kp O    &kp P
        &kp LSHFT  &kp A     &kp S    &kp D    &kp F         &kp H    &kp J    &kp K     &kp L    &kp SEMI
        &kp LCTRL  &kp Z     &kp X    &kp C    &kp V         &kp N    &kp M    &kp COMMA &kp DOT  &kp SLASH
        &mo NUM_G_L  &kp SPC         &kp RET &none
        >;
    };

    tron_base_layer {
      bindings = <
        &kp TJ_RA  &kp TJ_RU  &kp TJ_KO  &kp TJ_HA  &kp TJ_XYO    &kp TJ_KI  &kp TJ_RI  &kp TJ_KU     &kp TJ_A     &kp TJ_RE
        &kp TJ_TA  &kp TJ_TO  &kp TJ_KA  &kp TJ_TE  &kp TJ_MO     &kp TJ_WO  &kp TJ_I   &kp TJ_U      &kp TJ_SHI   &kp TJ_NN
        &kp TJ_MA  &kp TJ_NI  &kp TJ_SA  &kp TJ_NO  &kp TJ_NA     &kp TJ_SU  &kp TJ_TSU &kp TJ_DOUTEN &kp TJ_KUTEN &kp TJ_XTSU
        &lt TR_NUM_L BSPC  &sl TRR_L  &sl TRB_L    &trans
        >;
    };

    tron_blue_layer {
      bindings = <
        &TJ_BI     &TJ_ZO    &TJ_GO  &TJ_BA  &TJ_BO    &kp TJ_E   &trans     &kp TJ_ME         &kp TJ_MU &kp TJ_RO
        &TJ_DA     &TJ_DO    &TJ_GA  &TJ_DE  &TJ_BU    &kp TJ_O   &kp TJ_CHI &kp TJ_CHOUONNPU  &kp TJ_MI &kp TJ_YA
        &trans     &TJ_GE    &TJ_ZA  &TJ_ZE  &TJ_BE    &kp TJ_WA  &trans     &trans            &trans    &trans 
        &trans &sl TRP_L &trans &trans
        >;
    };

    tron_red_layer {
      bindings = <
        &kp TJ_HI   &kp TJ_SO  &kp TJ_NAKAGURO &kp TJ_XYA  &kp TJ_HO    &TJ_GI    &trans   &TJ_GU        &trans        &trans
        &kp TJ_NU   &kp TJ_NE  &kp TJ_XYU      &kp TJ_YO   &kp TJ_FU    &kp TJ_O  &TJ_DZI  &TJ_VU        &TJ_JI        &trans
        &trans      &kp TJ_KE  &kp TJ_YU       &kp TJ_SE   &kp TJ_HE    &TJ_ZU    &TJ_DZU  &TJ_LKAGIKAKO &TJ_RKAGIKAKO &trans
        &trans &trans &sl TRP_L &trans
        >;
    };

    tron_purple_layer {
      bindings = <
        &TJ_PI     &trans    &trans   &TJ_PA   &TJ_PO          &kp TJ_XE  &trans        &trans         &kp  TJ_XA     &trans
        &kp LANG5  &trans    &trans   &trans   &TJ_PU          &kp TJ_XO  &kp TJ_XI     &kp TJ_XU      &trans         &trans
        &trans     &trans    &trans   &trans   &TJ_PE          &trans     &kp LC(JP_J)  &kp LC(JP_K)   &kp LC(JP_L)   &kp LC(JP_SEMI)
        &kp INT5 &trans &trans &kp INT4
        >;
    };

    tron_num_layer {
      bindings = <
        &TJS_EXL    &TJ_LKAGIKAKO &TJ_RKAGIKAKO &TJS_COLON  &kp LC(F2)  &TJS_PLUS   &TJS_N7  &TJS_N8  &TJS_N9  &TJS_ASTRK
        &TJS_AMPS   &TJS_LPAR     &TJS_RPAR     &TJS_SEMI   &TJS_AT     &TJS_MINUS  &TJS_N4  &TJS_N5  &TJS_N6  &TJS_SLASH
        &TJS_QMARK  &TJS_UNDER    &TJS_DQT      &TJS_SQT    &TJS_PIPE   &TJS_EQUAL  &TJS_N1  &TJS_N2  &TJS_N3  &TJS_N0
        &trans     &trans       &kp RET      &mo TR_SYM_L
        >;
    };

    tron_sym_layer {
      bindings = <
        &trans  &trans  &trans  &trans      &kp KP_NLCK   &trans      &TJS_HASH  &TJS_LT    &TJS_GT    &TJS_CARET
        &trans  &trans  &trans  &trans      &kp INS       &TJS_TILDE  &TJS_PRNT  &TJS_LBRC  &TJS_RBRC  &TJS_GRAVE
        &trans  &trans  &trans  &trans      &trans        &kp NUBS    &TJS_YEN   &TJS_DLLR  &trans     &trans 
        &trans   &trans   &trans   &trans
        >;
    };


    
    nav_layer {
      bindings = <
        &trans     &trans     &trans     &trans     &trans           &kp LS(LG(N4))  &kp LS(LG(N3))  &kp LS(LG(N5))  &trans        &trans  
        &kp LEFT   &kp UP     &kp DOWN   &kp RIGHT  &kp HYPR(F)      &trans        &kp RCTRL       &kp RGUI        &kp RALT      &kp RSHFT
        &kp HOME   &kp PG_UP  &kp PG_DN  &kp END    &kp LG(TAB)      &kp HYPR(B)     &ck_pp          &kp C_VOL_DN    &kp C_VOL_UP  &kp C_MUTE
        &kp ESC    &kp TAB                                           &trans          &trans 
        >;
    };
 
    num_layer {
      bindings = <
        &kp JP_EXL   &kp JP_LBKT  &kp JP_RBKT   &kp JP_COLON  &kp INT1      &kp JP_PLUS   &kp JP_N7  &kp JP_N8  &kp JP_N9  &kp JP_ASTRK
        &kp JP_AMPS  &kp JP_LPAR  &kp JP_RPAR   &kp JP_SEMI   &kp JP_HASH   &jpkp_minus   &kp JP_N4  &kp JP_N5  &kp JP_N6  &kp JP_SLASH
        &kp JP_QMARK &kp JP_UNDER &kp JP_PRNT   &kp JP_AT     &kp JP_PIPE   &kp JP_EQUAL  &kp JP_N1  &kp JP_N2  &kp JP_N3  &kp JP_DOT
        &trans     &trans                                                   &kp RET       &kp JP_N0
        >;
    };

    sym_layer {
      bindings = <
        &trans     &kp LS(LG(G))  &kp LG(F)      &kp LG(G)  &kp K_CMENU       &kp LS(LA(N8)) &kp JP_HASH  &kp JP_LT     &kp JP_GT     &kp JP_CARET
        &trans     &kp LA(DEL)    &kp KP_ENTER   &kp DEL    &kp HYPR(Y)       &kp JP_TILDE   &kp JP_PRNT  &kp JP_LBRLS  &kp JP_RBRLS  &kp JP_GRAVE
        &kp CAPS   &defin         &gtran         &googl     &trans            &kp NUBS       &kp JP_YEN   &kp JP_DLLR   &kp LA(N3)    &kp LS(LA(N2))
        &trans   &trans                                                       &trans         &trans
        >;
    };

    fun_layer {
      bindings = <
        &trans   &trans    &trans   &trans        &kp KP_NLCK    &kp PSCRN        &kp F9     &kp F10    &kp F11     &kp F12
        &trans   &trans    &trans   &to QWE_G_L   &kp INS        &kp SLCK         &kp F5     &kp F6     &kp F7      &kp F8
        &trans   &trans    &trans   &to SDY_L     &kp K_MENU     &kp PAUSE_BREAK  &kp F1     &kp F2     &kp F3      &kp F4
        &none     &kp K_APP                                      &kp KP_NLCK      &kp INS
        >;
    };

     num_gaming_layer {
      bindings = <
        &kp ESC   &kp N7    &kp N8    &kp N9   &kp T     &trans    &kp F21    &kp F22    &kp F23    &kp F24
        &kp TAB   &kp N4    &kp N5    &kp N6   &kp G     &trans    &kp F17    &kp F18    &kp F19    &kp F20
        &kp N0    &kp N1    &kp N2    &kp N3   &kp B     &trans    &kp F13    &kp F14    &kp F15    &kp F16
        &none     &none                                  &none     &none 
        >;
    };

        
    num_word_layer {
      bindings = <
        &kp JP_EXL   &kp JP_LBKT  &kp JP_RBKT   &kp JP_COLON  &kp LC(F2)    &kp JP_PLUS   &kp JP_N7  &kp JP_N8  &kp JP_N9  &kp JP_ASTRK
        &kp JP_AMPS  &kp JP_LPAR  &kp JP_RPAR   &kp JP_SEMI   &kp JP_HASH   &kp JP_MINUS  &kp JP_N4  &kp JP_N5  &kp JP_N6  &kp JP_SLASH
        &kp JP_QMARK &kp JP_UNDER &kp JP_PRNT    &kp JP_AT    &kp JP_PIPE   &kp JP_EQUAL  &kp JP_N1  &kp JP_N2  &kp JP_N3  &kp JP_DOT
        &trans     &nw_spc       &trans      &kp JP_N0
        >;
    };
    ble_layer {
      bindings = <
        &bt BT_CLR   &trans        &trans       &trans       &sys_reset     &trans      &trans      &trans     &trans     &trans
        &trans       &trans        &trans       &trans       &bootloader    &trans      &trans      &trans     &trans     &trans
        &bt BT_SEL 4 &bt BT_SEL 3  &bt BT_SEL 2 &bt BT_SEL 1 &bt BT_SEL 0   &trans      &trans      &trans     &trans     &trans 
        &trans          &trans       &trans           &trans
        >;
    };

    meh_layer {
      bindings = <
        &kp MEH(X)   &kp MEH(N1)  &kp MEH(N2)   &kp MEH(N3)   &kp MEH(P)   &kp C_EJECT   &kp F21   &kp F22   &kp F23    &kp F24
        &kp MEH(S)   &kp MEH(N8)  &kp MEH(N9)   &kp MEH(D)    &kp MEH(F)   &trans        &kp F17   &kp F18   &kp F19    &kp F20
        &kp MEH(V)   &kp MEH(K)   &kp MEH(J)    &kp MEH(G)    &kp MEH(W)   &trans        &kp F13   &kp F14   &kp F15    &kp F16
        &kp MEH(N4) &kp MEH(N)                &kp C_AL_CONTROL_PANEL        &kp GLOBE
        >;
    };
    short_ext_word_mac_layer {
      bindings = <
        &trans     &trans     &trans    &trans              &trans          &trans    &trans              &trans    &trans    &trans 
        &trans     &trans     &trans    &selword_f_mac_rep  &trans          &trans    &selword_f_mac_rep  &trans    &trans    &trans 
        &trans     &trans     &trans    &trans              &trans          &trans    &trans              &trans    &trans    &trans 
        &trans     &trans     &selword_f_mac_rep    &trans
        >;
    };    
    short_ext_line_layer {
      bindings = <
        &trans     &trans     &trans    &trans          &trans          &trans     &trans           &trans    &trans    &trans 
        &trans     &trans     &trans    &selline_f_rep  &trans          &trans     &selline_f_rep   &trans    &trans    &trans 
        &trans     &trans     &trans    &trans          &trans          &trans     &trans           &trans    &trans    &trans 
        &trans     &trans     &selline_f_rep    &trans
        >;
    };    
  };
};
